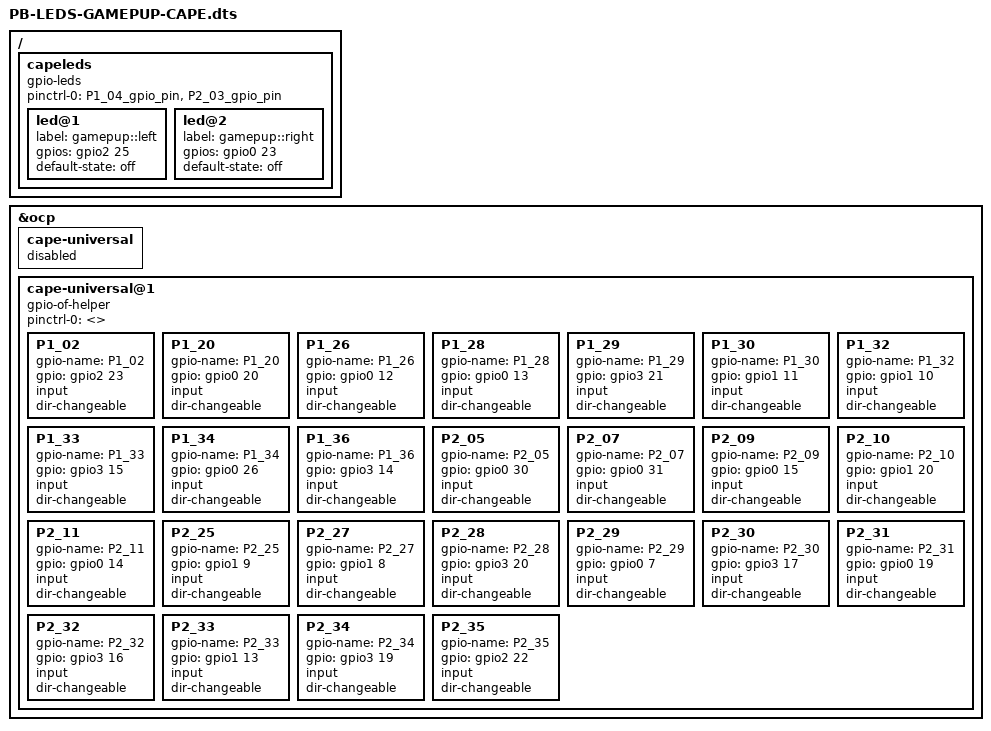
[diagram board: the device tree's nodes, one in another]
/*
 * Copyright (C) 2012 Texas Instruments Incorporated - http://www.ti.com/
 *
 * This program is free software; you can redistribute it and/or modify
 * it under the terms of the GNU General Public License version 2 as
 * published by the Free Software Foundation.
 */
/dts-v1/;
/plugin/;

#include <dt-bindings/gpio/gpio.h>
#include <dt-bindings/pinctrl/am33xx.h>
#include <dt-bindings/interrupt-controller/irq.h>

/ {
	/*
	 * Free up the pins used by the cape from the pinmux helpers.
	 *
	 * This is not required as the default pinmux is gpio.
	 */
#if 0
	fragment@0 {
		target = <&ocp>;
		__overlay__ {
			P1_04_pinmux { status = "disabled"; };	/* LEDs - left */
			P2_03_pinmux { status = "disabled"; };	/* LEDs - right */
		};
	};
#endif

	/*
	 * Free up the gpios used by the cape-universal gpio helpers.
	 */
	fragment@1 {
		target = <&ocp>;
		__overlay__ {
			cape-universal { status = "disabled"; };
		};
	};

	/*
	 * Make a new set of gpio helpers.
	 */
	fragment@2 {
		target = <&ocp>;
		__overlay__ {
			cape-universal@1 {
				compatible = "gpio-of-helper";
				status = "okay";
				pinctrl-names = "default";
				pinctrl-0 = <>;

				P1_02 {
					gpio-name = "P1_02";
					gpio = <&gpio2 23 0>;
					input;
					dir-changeable;
				};

				P1_20 {
					gpio-name = "P1_20";
					gpio = <&gpio0 20 0>;
					input;
					dir-changeable;
				};

				P1_26 {
					gpio-name = "P1_26";
					gpio = <&gpio0 12 0>;
					input;
					dir-changeable;
				};

				P1_28 {
					gpio-name = "P1_28";
					gpio = <&gpio0 13 0>;
					input;
					dir-changeable;
				};

				P1_29 {
					gpio-name = "P1_29";
					gpio = <&gpio3 21 0>;
					input;
					dir-changeable;
				};

				P1_30 {
					gpio-name = "P1_30";
					gpio = <&gpio1 11 0>;
					input;
					dir-changeable;
				};

				P1_32 {
					gpio-name = "P1_32";
					gpio = <&gpio1 10 0>;
					input;
					dir-changeable;
				};

				P1_33 {
					gpio-name = "P1_33";
					gpio = <&gpio3 15 0>;
					input;
					dir-changeable;
				};

				P1_34 {
					gpio-name = "P1_34";
					gpio = <&gpio0 26 0>;
					input;
					dir-changeable;
				};

				P1_36 {
					gpio-name = "P1_36";
					gpio = <&gpio3 14 0>;
					input;
					dir-changeable;
				};

				P2_05 {
					gpio-name = "P2_05";
					gpio = <&gpio0 30 0>;
					input;
					dir-changeable;
				};

				P2_07 {
					gpio-name = "P2_07";
					gpio = <&gpio0 31 0>;
					input;
					dir-changeable;
				};

				P2_09 {
					gpio-name = "P2_09";
					gpio = <&gpio0 15 0>;
					input;
					dir-changeable;
				};

				P2_10 {
					gpio-name = "P2_10";
					gpio = <&gpio1 20 0>;
					input;
					dir-changeable;
				};

				P2_11 {
					gpio-name = "P2_11";
					gpio = <&gpio0 14 0>;
					input;
					dir-changeable;
				};

				P2_25 {
					gpio-name = "P2_25";
					gpio = <&gpio1 9 0>;
					input;
					dir-changeable;
				};

				P2_27 {
					gpio-name = "P2_27";
					gpio = <&gpio1 8 0>;
					input;
					dir-changeable;
				};

				P2_28 {
					gpio-name = "P2_28";
					gpio = <&gpio3 20 0>;
					input;
					dir-changeable;
				};

				P2_29 {
					gpio-name = "P2_29";
					gpio = <&gpio0 7 0>;
					input;
					dir-changeable;
				};

				P2_30 {
					gpio-name = "P2_30";
					gpio = <&gpio3 17 0>;
					input;
					dir-changeable;
				};

				P2_31 {
					gpio-name = "P2_31";
					gpio = <&gpio0 19 0>;
					input;
					dir-changeable;
				};

				P2_32 {
					gpio-name = "P2_32";
					gpio = <&gpio3 16 0>;
					input;
					dir-changeable;
				};

				P2_33 {
					gpio-name = "P2_33";
					gpio = <&gpio1 13 0>;
					input;
					dir-changeable;
				};

				P2_34 {
					gpio-name = "P2_34";
					gpio = <&gpio3 19 0>;
					input;
					dir-changeable;
				};

				P2_35 {
					gpio-name = "P2_35";
					gpio = <&gpio2 22 0>;
					input;
					dir-changeable;
				};
			};
		};
	};

	/*
	 * Load the drivers for the LEDs.
	 */
	fragment@3 {
		target-path="/";
		__overlay__ {
			capeleds {
				compatible = "gpio-leds";
		
				pinctrl-names = "default";
				pinctrl-0 = <
					&P1_04_gpio_pin	/* left */
					&P2_03_gpio_pin	/* right */
				>;
		
				led@1 {
					label = "gamepup::left";
					gpios = <&gpio2 25 GPIO_ACTIVE_HIGH>;
					default-state = "off";
				};
		
				led@2 {
					label = "gamepup::right";
					gpios = <&gpio0 23 GPIO_ACTIVE_HIGH>;
					default-state = "off";
				};
			};
		};
	};
};
						
